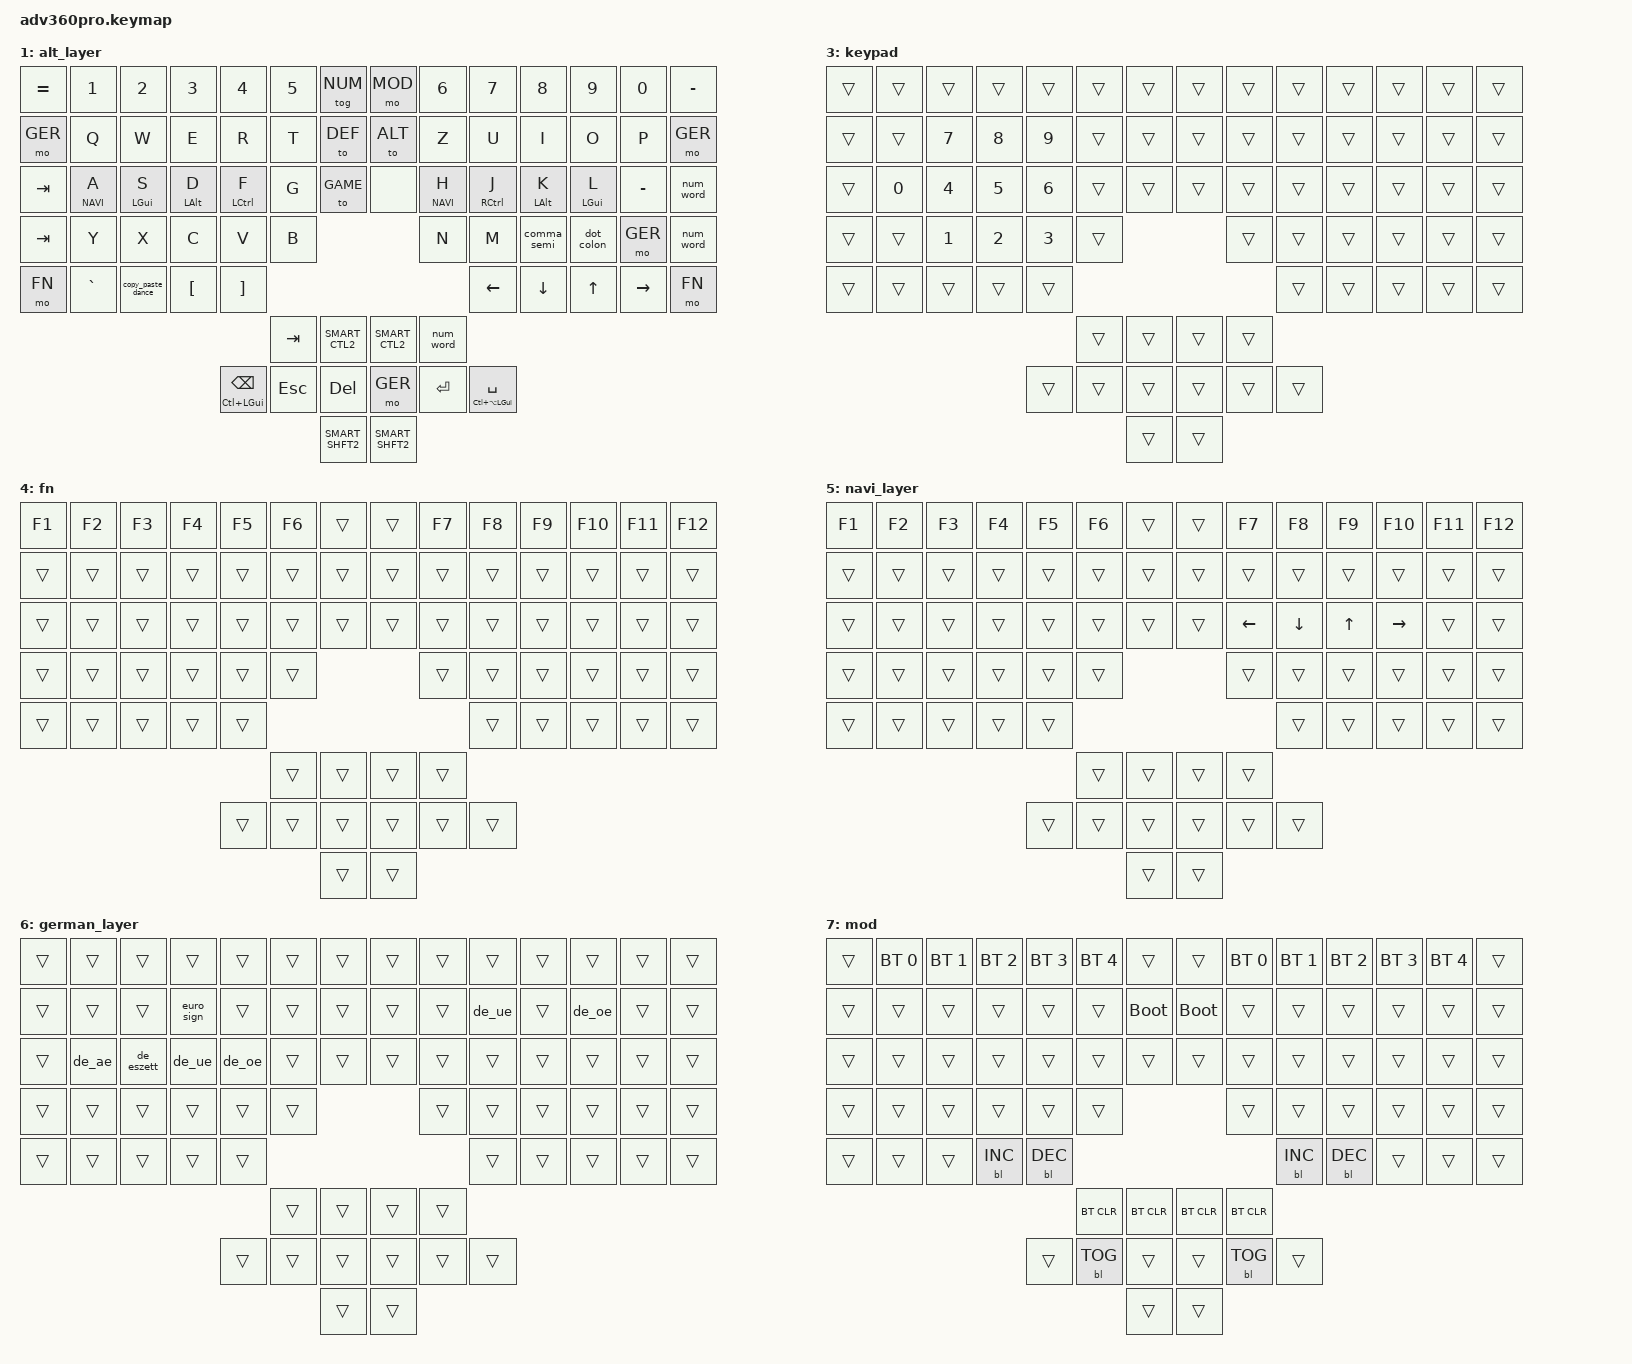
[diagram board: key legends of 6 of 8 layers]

/*                                 ADVANTAGE 360 KEY MATRIX / LAYOUT MAPPING
 ╭────────────────────────────┬────────────────────────────╮ ╭────────────────────────────┬────────────────────────────╮
 │  0   1   2   3   4   5   6 │  7   8   9  10  11  12  13 │ │ LN5 LN4 LN3 LN2 LN1 LN0 -- │ --  RN0 RN1 RN2 RN3 RN4 RN5│
 │ 14  15  16  17  18  19  20 │ 21  22  23  24  25  26  27 │ │ LT5 LT4 LT3 LT2 LT1 LT0 -- │ --  RT0 RT1 RT2 RT3 RT4 RT5│
 │ 28  29  30  31  32  33  34 │ 35  36  37  38  39  40  41 │ │ LM5 LM4 LM3 LM2 LM1 LM0 -- │ --  RM0 RM1 RM2 RM3 RM4 RM5│
 │ 42  43  44  45  46  47 ╭───┴───╮ 48  49  50  51  52  53 │ │ LB5 LB4 LB3 LB2 LB1 LB0╭───┴───╮ RB0 RB1 RB2 RB3 RB4 RB5│
 │ 54  55  56  57  58╭────╯       ╰────╮59  60  61  62  63 │ │ --  --  --  --  --╭────╯       ╰────╮--  --  --  --  -- │
 ╰───────────────────┼────────┬────────┼───────────────────╯ ╰───────────────────┼────────┬────────┼───────────────────╯
                 ╭───╯ 64  65 │ 66  67 ╰───╮                                 ╭───╯ --  -- │ --  -- ╰───╮
                 │ 68  69  70 │ 71  72  73 │                                 │ LH1 LH0 -- │ --  RH0 RH1│
                 ╰───────╮ 74 │ 75 ╭───────╯                                 ╰───────╮ -- │ -- ╭───────╯
                         ╰────┴────╯                                                 ╰────┴────╯ */

#include <behaviors.dtsi>
#include <dt-bindings/zmk/keys.h>
#include <dt-bindings/zmk/bt.h>
#include <dt-bindings/zmk/outputs.h>
#include <dt-bindings/zmk/rgb.h>
#include <dt-bindings/zmk/backlight.h>

#include "nodefree_keypos_adv360.h"
#include "nodefree_helper.h"
#include "nodefree_german.dtsi"

#define XXX &none
#define ___ &trans

#define DEF 0
#define ALT 1
#define GAME 2
#define NUM 3
#define FN 4
#define NAVI 5
#define GER 6
#define MOD 7

#include "combos.dtsi"
#include "custom_behaviors.h"

/ {

behaviors {
		        navi_word: behavior_navi_word {
			compatible = "zmk,behavior-caps-word";
			label = "NAVI_WORD";
			#binding-cells = <0>;
                        layers = <NAVI>;  
			continue-list = <LSHFT RSHFT DEL BSPC TAB LEFT DOWN UP RIGHT>;
		};
	};

    /* remove unused keys from layout and move thumb cluster to bottom */
    chosen {
        zmk,matrix_transform = &urobs_transform;
    };

    keymap {
        compatible = "zmk,keymap";


        main_layer {
            bindings = <
                &kp EQUAL &kp N1    &kp N2    &kp N3    &kp N4    &kp N5    &tog NUM    &mo MOD   &kp N6    &kp N7    &kp N8    &kp N9    &kp N0    &kp MINUS
                &kp TAB   &kp Q     &kp W     &kp E     &kp R     &kp T     &to DEF         &to ALT   &kp Z     &kp U     &kp I     &kp O     &kp P     &kp TAB
                &kp ESC   &hml_layer NAVI A    &hml LGUI S     &hml LALT D     &hml LCTRL F     &kp G     &to GAME    &none     &hmr_layer NAVI H     &hmr RCTRL J     &hmr LALT K     &hmr LGUI L     &kp MINUS  &kp ENTER
                &kp LSHFT &kp Y     &kp X     &kp C     &kp V     &kp B                              &kp N     &kp M     &comma_semi &dot_colon   &mo GER  &kp RSHFT
                &mo FN    &kp GRAVE &copy_paste_dance  &kp LBKT  &kp RBKT                                              &kp LEFT    &kp DOWN  &kp UP  &kp RIGHT  &mo FN
                                                                SMART_CTL2 &home_end       &pg_up_dn   SMART_CTL2  
                                        &hml LC(LGUI) BSPC &kp ESC &kp DEL                     &mo GER  &kp ENTER &hmr LC(LA(LGUI)) SPACE
                                                                            SMART_SHFT2       SMART_SHFT2 
                >;
        };

        alt_layer {
            bindings = <
                &kp EQUAL &kp N1    &kp N2    &kp N3    &kp N4    &kp N5    &tog NUM    &mo MOD   &kp N6    &kp N7    &kp N8    &kp N9    &kp N0    &kp MINUS
                &mo GER   &kp Q     &kp W     &kp E     &kp R     &kp T     &to DEF         &to ALT   &kp Z     &kp U     &kp I     &kp O     &kp P     &mo GER
                &kp TAB   &hml_layer NAVI A    &hml LGUI S     &hml LALT D     &hml LCTRL F     &kp G     &to GAME    &none     &hmr_layer NAVI H     &hmr RCTRL J     &hmr LALT K     &hmr LGUI L     &kp MINUS  &num_word
                &kp TAB &kp Y     &kp X     &kp C     &kp V     &kp B                              &kp N     &kp M     &comma_semi &dot_colon   &mo GER  &num_word
                &mo FN    &kp GRAVE &copy_paste_dance  &kp LBKT  &kp RBKT                                              &kp LEFT    &kp DOWN  &kp UP  &kp RIGHT  &mo FN
                                                                &kp TAB SMART_CTL2       SMART_CTL2   &num_word 
                                        &hml LC(LGUI) BSPC &kp ESC &kp DEL                     &mo GER  &kp ENTER &hmr LC(LA(LGUI)) SPACE
                                                                            SMART_SHFT2       SMART_SHFT2 
                >;
        };

        game_layer {
            bindings = <
                &kp EQUAL &kp N1    &kp N2    &kp N3    &kp N4    &kp N5    &tog NUM    &mo MOD   &kp N6    &kp N7    &kp N8    &kp N9    &kp N0    &kp MINUS
                &kp TAB   &kp Q     &kp W     &kp E     &kp R     &kp T     &to DEF         &none   &kp Z     &kp U     &kp I     &kp O     &kp P     &kp TAB
                &kp ESC   &kp A    &kp S     &kp D     &kp F     &kp G     &to GAME    &none     &kp H     &kp J     &kp K     &kp L     &kp MINUS  &kp ENTER
                &kp LSHFT &kp Y     &kp X     &kp C     &kp V     &kp B                              &kp N     &kp M     &comma_semi &dot_colon   &qmark_excl  &kp RSHFT
                &mo FN    &kp GRAVE &copy_paste_dance  &kp LBKT  &kp RBKT                                              &kp LEFT    &kp DOWN  &kp UP  &kp RIGHT  &mo FN
                                                                SMART_CTL2 &home_end       &pg_up_dn  SMART_CTL2  
                                        &hml LC(LGUI) BSPC &kp SPACE &kp DEL                     &mo GER  &kp ENTER &hmr LC(LA(LGUI)) SPACE
                                                                            SMART_SHFT2       SMART_SHFT2 
                >;
        };

        keypad {
            bindings = <
                ___       ___       ___       ___       ___       ___       ___            ___       ___       ___       ___       ___       ___       ___
                ___       ___      &kp N7    &kp N8    &kp N9    ___       ___            ___       ___       ___       ___       ___       ___       ___
                ___       &kp N0     &kp N4    &kp N5    &kp N6    ___       ___            ___       ___       ___       ___       ___       ___       ___
                ___       ___       &kp N1    &kp N2    &kp N3    ___                                ___       ___       ___       ___       ___       ___
                ___       ___       ___       ___       ___                                                    ___       ___       ___       ___       ___
                                                                  ___       ___            ___       ___
                                                        ___       ___       ___            ___       ___       ___
                                                                            ___            ___
            >;
        };

        fn {
            bindings = <
                &kp F1    &kp F2    &kp F3    &kp F4    &kp F5    &kp F6    ___            ___       &kp F7    &kp F8    &kp F9    &kp F10   &kp F11   &kp F12
                ___       ___       ___       ___       ___       ___       ___            ___       ___       ___       ___       ___       ___       ___
                ___       ___       ___       ___       ___       ___       ___            ___       ___       ___       ___       ___       ___       ___
                ___       ___       ___       ___       ___       ___                                ___       ___       ___       ___       ___       ___
                ___       ___       ___       ___       ___                                                    ___       ___       ___       ___       ___
                                                                  ___       ___            ___       ___
                                                        ___       ___       ___            ___       ___       ___
                                                                            ___            ___
            >;
        };

        navi_layer {
                    bindings = <
                        &kp F1    &kp F2    &kp F3    &kp F4    &kp F5    &kp F6    ___            ___       &kp F7    &kp F8    &kp F9    &kp F10   &kp F11   &kp F12
                        ___       ___       ___       ___       ___       ___       ___            ___       ___       ___       ___       ___       ___       ___
                        ___       ___       ___       ___       ___       ___       ___            ___       &kp LEFT    &kp DOWN  &kp UP  &kp RIGHT       ___       ___
                        ___       ___       ___       ___       ___       ___                                ___       ___       ___       ___       ___       ___
                        ___       ___       ___       ___    ___                                             ___    ___    ___       ___       ___
                                                                          ___    ___            ___       ___
                                                                ___    ___    ___         ___    ___    ___
                                                                                    ___         ___
                    >;
                };

        german_layer {
            bindings = <
                ___       ___       ___       ___       ___       ___       ___            ___       ___       ___       ___       ___       ___       ___
                ___       ___       ___       &euro_sign       ___       ___       ___            ___       ___       &de_ue       ___       &de_oe       ___       ___
                ___       &de_ae       &de_eszett       &de_ue     &de_oe       ___       ___            ___       ___       ___       ___       ___       ___       ___
                ___       ___       ___       ___       ___       ___                                ___       ___       ___       ___       ___       ___
                ___       ___       ___       ___       ___                                                    ___       ___       ___       ___       ___
                                                                  ___       ___            ___       ___
                                                        ___       ___       ___            ___       ___       ___
                                                                            ___            ___
            >;
        };

        mod {
            bindings = <
                ___       &bt BT_SEL 0 &bt BT_SEL 1 &bt BT_SEL 2 &bt BT_SEL 3 &bt BT_SEL 4 ___              ___         &bt BT_SEL 0 &bt BT_SEL 1     &bt BT_SEL 2 &bt BT_SEL 3 &bt BT_SEL 4 ___
                ___       ___          ___          ___          ___          ___          &bootloader      &bootloader ___          ___              ___          ___          ___          ___
                ___       ___          ___          ___          ___          ___          ___              ___         ___          ___              ___          ___          ___          ___
                ___       ___          ___          ___          ___          ___                                       ___          ___              ___          ___          ___          ___
                ___       ___          ___          &bl BL_INC   &bl BL_DEC                                                          &bl BL_INC       &bl BL_DEC   ___          ___          ___
                                                                              &bt BT_CLR   &bt BT_CLR       &bt BT_CLR  &bt BT_CLR
                                                                 ___          &bl BL_TOG   ___              ___         &bl BL_TOG   ___
                                                                                           ___              ___
            >;
        };

       

    };

};

